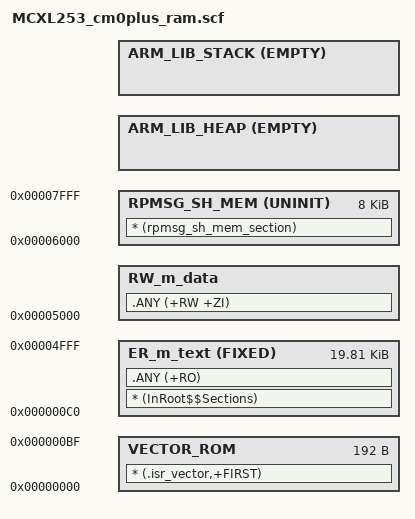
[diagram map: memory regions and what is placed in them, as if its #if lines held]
#!armclang --target=arm-arm-none-eabi -march=armv8-m.main -E -x c
/*
** ###################################################################
**     Processors:          MCXL253VDF_cm0plus
**                          MCXL253VLL_cm0plus
**
**     Compiler:            Keil ARM C/C++ Compiler
**     Reference manual:    MCXL25xRM DraftH
**     Version:             rev. 1.0, 2025-06-13
**     Build:               b250814
**
**     Abstract:
**         Linker file for the Keil ARM C/C++ Compiler
**
**     Copyright 2016 Freescale Semiconductor, Inc.
**     Copyright 2016-2025 NXP
**     SPDX-License-Identifier: BSD-3-Clause
**
**     http:                 www.nxp.com
**     mail:                 support@nxp.com
**
** ###################################################################
*/


/* Sizes */
#if (defined(__stack_size__))
  #define Stack_Size                   __stack_size__
#else
  #define Stack_Size                   0x0400
#endif

#if (defined(__heap_size__))
  #define Heap_Size                    __heap_size__
#else
  #define Heap_Size                    0x0400
#endif

#define  m_interrupts_start            0x00000000
#define  m_interrupts_size             0x000000C0

#define  m_text_start                  0x000000C0
#define  m_text_size                   0x00004F40

#if (defined(__use_shmem__))
  #define  m_data_start                0x00005000
  #define  m_data_size                 0x00001000
  #define  m_rpmsg_sh_mem_start        0x00006000
  #define  m_rpmsg_sh_mem_size         0x00002000
#else
  #define  m_data_start                0x00005000
  #define  m_data_size                 0x00003000
#endif

LR_m_text m_interrupts_start m_interrupts_size+m_text_size {   ; load region size_region

  VECTOR_ROM m_interrupts_start m_interrupts_size { ; load address = execution address
    * (.isr_vector,+FIRST)
  }

  ER_m_text m_text_start FIXED m_text_size { ; load address = execution address
    * (InRoot$$Sections)
    .ANY (+RO)
  }

  RW_m_data m_data_start m_data_size-Stack_Size-Heap_Size { ; RW data
    .ANY (+RW +ZI)
  }

#if (defined(__use_shmem__))
  RPMSG_SH_MEM m_rpmsg_sh_mem_start UNINIT m_rpmsg_sh_mem_size { ; Shared memory used by RPMSG
    * (rpmsg_sh_mem_section)
  }
#endif

  ARM_LIB_HEAP +0 EMPTY Heap_Size {    ; Heap region growing up
  }
  ARM_LIB_STACK m_data_start+m_data_size EMPTY -Stack_Size { ; Stack region growing down
  }
}
